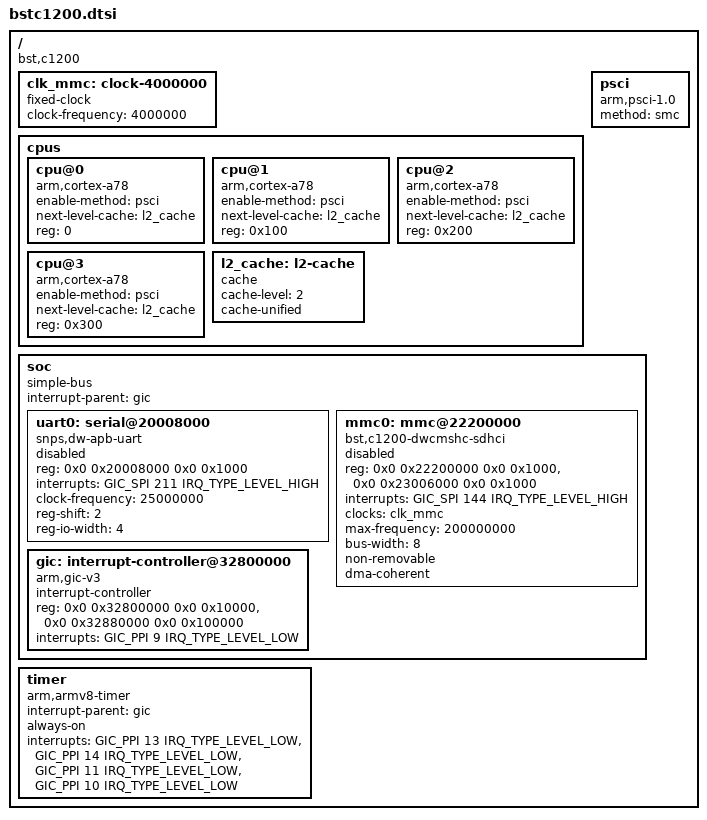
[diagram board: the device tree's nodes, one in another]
// SPDX-License-Identifier: GPL-2.0
#include <dt-bindings/interrupt-controller/arm-gic.h>
#include <dt-bindings/interrupt-controller/irq.h>

/ {
	compatible = "bst,c1200";
	#address-cells = <2>;
	#size-cells = <2>;

	clk_mmc: clock-4000000 {
		compatible = "fixed-clock";
		#clock-cells = <0>;
		clock-frequency = <4000000>;
	};

	cpus {
		#address-cells = <1>;
		#size-cells = <0>;

		cpu@0 {
			compatible = "arm,cortex-a78";
			device_type = "cpu";
			enable-method = "psci";
			next-level-cache = <&l2_cache>;
			reg = <0>;
		};

		cpu@1 {
			compatible = "arm,cortex-a78";
			device_type = "cpu";
			enable-method = "psci";
			next-level-cache = <&l2_cache>;
			reg = <0x100>;
		};

		cpu@2 {
			compatible = "arm,cortex-a78";
			device_type = "cpu";
			enable-method = "psci";
			next-level-cache = <&l2_cache>;
			reg = <0x200>;
		};

		cpu@3 {
			compatible = "arm,cortex-a78";
			device_type = "cpu";
			enable-method = "psci";
			next-level-cache = <&l2_cache>;
			reg = <0x300>;
		};

		l2_cache: l2-cache {
			compatible = "cache";
			cache-level = <2>;
			cache-unified;
		};
	};

	psci {
		compatible = "arm,psci-1.0";
		method = "smc";
	};

	soc {
		compatible = "simple-bus";
		#address-cells = <2>;
		#size-cells = <2>;
		ranges;
		interrupt-parent = <&gic>;

		uart0: serial@20008000 {
			compatible = "snps,dw-apb-uart";
			reg = <0x0 0x20008000 0x0 0x1000>;
			interrupts = <GIC_SPI 211 IRQ_TYPE_LEVEL_HIGH>;
			clock-frequency = <25000000>;
			reg-shift = <2>;
			reg-io-width = <4>;
			status = "disabled";
		};

		mmc0: mmc@22200000 {
			compatible = "bst,c1200-dwcmshc-sdhci";
			reg = <0x0 0x22200000 0x0 0x1000>,
			      <0x0 0x23006000 0x0 0x1000>;
			interrupts = <GIC_SPI 144 IRQ_TYPE_LEVEL_HIGH>;
			clocks = <&clk_mmc>;
			clock-names = "core";
			max-frequency = <200000000>;
			bus-width = <8>;
			non-removable;
			dma-coherent;
			status = "disabled";
		};

		gic: interrupt-controller@32800000 {
			compatible = "arm,gic-v3";
			#interrupt-cells = <3>;
			#address-cells = <2>;
			#size-cells = <2>;
			interrupt-controller;
			ranges;
			reg = <0x0 0x32800000 0x0 0x10000>,
			      <0x0 0x32880000 0x0 0x100000>;
			interrupts = <GIC_PPI 9 IRQ_TYPE_LEVEL_LOW>;
		};
	};

	timer {
		compatible = "arm,armv8-timer";
		interrupt-parent = <&gic>;
		always-on;
		interrupts = <GIC_PPI 13 IRQ_TYPE_LEVEL_LOW>,
			     <GIC_PPI 14 IRQ_TYPE_LEVEL_LOW>,
			     <GIC_PPI 11 IRQ_TYPE_LEVEL_LOW>,
			     <GIC_PPI 10 IRQ_TYPE_LEVEL_LOW>;
	};
};
